# COMPUTE_CLUSTER_ARM_COREPACK_0_COMPUTE_CLUSTER_ARM_COREPACK_0_APBADDR_DBG_CPU0_000730010000h register map
Vendor: Texas Instruments
Peripheral module from a debugger description file (folder am62L).
Registers are 32-bit, read-write, reset 0x0 unless marked. A register's access mark holds for its fields unless they carry their own. Offsets are as the file gives them; lines under a group give offsets from that group; [hi:lo] are bit positions; {n}, {i} and the like mark numbered series; 'fields as' and 'values as' point back to an identical list; <NAME> marks a mode.

## COMPUTE_CLUSTER_ARM_COREPACK_0_APBADDR_DBG_CPU0 (part 1 of 2)
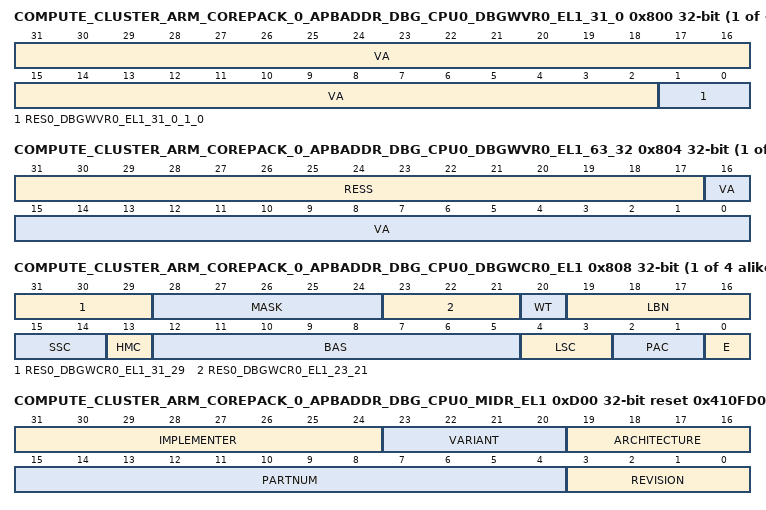
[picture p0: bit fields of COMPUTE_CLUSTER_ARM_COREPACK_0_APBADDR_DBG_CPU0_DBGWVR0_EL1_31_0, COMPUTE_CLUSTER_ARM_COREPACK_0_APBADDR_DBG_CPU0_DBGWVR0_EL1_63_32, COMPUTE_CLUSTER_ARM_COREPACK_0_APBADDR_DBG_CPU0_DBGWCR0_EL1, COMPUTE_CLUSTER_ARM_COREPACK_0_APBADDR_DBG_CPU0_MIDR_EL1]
{0x800+0x10*i} COMPUTE_CLUSTER_ARM_COREPACK_0_APBADDR_DBG_CPU0_DBGWVR{i}_EL1_31_0 (i=0..3) — Debug Watchpoint Value Register {i}
  [31:2] VA — Bits[48:2] of the address value for comparison.ARM deprecates setting DBGWVR<n>_EL1[2] == 1.
  [1:0] RES0_DBGWVR{i}_EL1_31_0_1_0 — Reserved, RES0.
{0x804+0x10*i} COMPUTE_CLUSTER_ARM_COREPACK_0_APBADDR_DBG_CPU0_DBGWVR{i}_EL1_63_32 (i=0..3) — Debug Watchpoint Extended Value Register {i}
  [31:17] RESS — Reserved, Sign extended. Hardwired to the value of the sign bit, bit [48]. Hardware and software must treat this field as RES0 if bit[48] is 0, and as RES1 if bit[48] is 1.
  [16:0] VA — Bits[48:2] of the address value for comparison.ARM deprecates setting DBGWVR<n>_EL1[2] == 1.
{0x808+0x10*i} COMPUTE_CLUSTER_ARM_COREPACK_0_APBADDR_DBG_CPU0_DBGWCR{i}_EL1 (i=0..3) — Debug Watchpoint Control Register {i}
  [31:29] RES0_DBGWCR{i}_EL1_31_29 — Reserved, RES0.
  [28:24] MASK — Address mask. Only objects up to 2GB can be watched using a single mask. 00000 No mask. 00001 Reserved. 00010 Reserved. Other values mask the corresponding number of address bits, from 0b00011 masking 3 address bits [0x00000007 mask for address] to 0b11111 masking 31 address bits [0x7FFFFFFF mask for address].
  [23:21] RES0_DBGWCR{i}_EL1_23_21 — Reserved, RES0.
  [20] WT — Watchpoint type. Possible values are: 0 Unlinked data address match. 1 Linked data address match.
  [19:16] LBN — Linked breakpoint number. For Linked data address watchpoints, this specifies the index of the Context-matching breakpoint linked to.
  [15:14] SSC — Security state control. Determines the security states under which a watchpoint debug event for watchpoint n is generated. This field must be interpreted along with the HMC and PAC fields.
  [13] HMC — Higher mode control. Determines the debug perspective for deciding when a watchpoint debug event for watchpoint n is generated. This field must be interpreted along with the SSC and PAC fields.
  [12:5] BAS — Byte address select. Each bit of this field selects whether a byte from within the word or double-word addressed by DBGWVR<n>_EL1 is being watched.BASDescriptionxxxxxxx1Match byte at DBGWVR<n>_EL1xxxxxx1xMatch byte at DBGWVR<n>_EL1+1xxxxx1xxMatch byte at DBGWVR<n>_EL1+2xxxx1xxxMatch byte at DBGWVR<n>_EL1+3In cases where DBGWVR<n>_EL1 addresses a double-word:BASDescription, if DBGWVR<n>_EL1[2] == 0xxx1xxxxMatch byte at DBGWVR<n>_EL1+4xx1xxxxxMatch byte at DBGWVR<n>_EL1+5x1xxxxxxMatch byte at DBGWVR<n>_EL1+61xxxxxxxMatch byte at DBGWVR<n>_EL1+7If DBGWVR<n>_EL1[2] == 1, only BAS[3:0] is used. ARM deprecates setting DBGWVR<n>_EL1 == 1.The valid values for BAS are 0b0000000, or a binary number all of whose set bits are contiguous. All other values are reserved and must not be used by software.If BAS is zero, no bytes are watched by this watchpoint.Ignored if E is 0.
  [4:3] LSC — Load/store control. This field enables watchpoint matching on the type of access being made. Possible values of this field are: 01 Match instructions that load from a watchpointed address. 10 Match instructions that store to a watchpointed address. 11 Match instructions that load from or store to a watchpointed address. All other values are reserved, but must behave as if the watchpoint is disabled. Software must not rely on this property as the behavior of reserved values might change in a future revision of the architecture.Ignored if E is 0.
  [2:1] PAC — Privilege of access control. Determines the exception level or levels at which a watchpoint debug event for watchpoint n is generated. This field must be interpreted along with the SSC and HMC fields.
  [0] E — Enable watchpoint n. Possible values are: 0 Watchpoint disabled. 1 Watchpoint enabled.
0xD00 COMPUTE_CLUSTER_ARM_COREPACK_0_APBADDR_DBG_CPU0_MIDR_EL1 reset 0x410FD034 — Main ID Register
  [31:24] IMPLEMENTER — The Implementer code. This field must hold an implementer code that has been assigned by ARM.
  [23:20] VARIANT — An IMPLEMENTATION DEFINED variant number. Typically this field is used to distinguish between different product variants or major revisions of a product.
  [19:16] ARCHITECTURE
  [15:4] PARTNUM — An IMPLEMENTATION DEFINED primary part number for the device. On processors implemented by ARM if the top four bits of the primary part number are 0x0 or 0x7 the variant and architecture are encoded differently
  [3:0] REVISION — An IMPLEMENTATION DEFINED revision number for the device
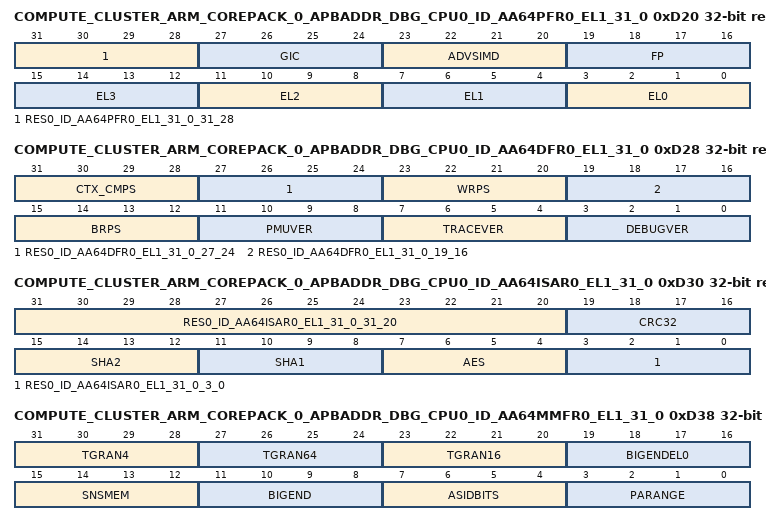
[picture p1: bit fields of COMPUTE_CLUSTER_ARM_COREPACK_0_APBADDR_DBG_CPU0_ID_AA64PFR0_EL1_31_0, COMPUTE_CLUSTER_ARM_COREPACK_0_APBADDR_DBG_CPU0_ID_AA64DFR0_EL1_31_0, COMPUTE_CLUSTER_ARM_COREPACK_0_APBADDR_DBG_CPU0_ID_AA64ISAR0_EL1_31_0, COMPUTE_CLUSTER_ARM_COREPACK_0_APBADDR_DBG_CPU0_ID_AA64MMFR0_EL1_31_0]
0xD20 COMPUTE_CLUSTER_ARM_COREPACK_0_APBADDR_DBG_CPU0_ID_AA64PFR0_EL1_31_0 reset 0x1002222 — Processor Feature Register 0 (low word)
  [31:28] RES0_ID_AA64PFR0_EL1_31_0_31_28 — Reserved, RES0.
  [27:24] GIC — GIC system register interface. Permitted values are: 0000 No GIC system registers are supported. 0001 GICv3 system registers are supported. All other values are reserved.
  [23:20] ADVSIMD — Advanced SIMD. Permitted values are: 0000 Advanced SIMD is implemented. 1111 Advanced SIMD is not implemented. All other values are reserved.
  [19:16] FP — Floating-point. Permitted values are: 0000 Floating-point is implemented. 1111 Floating-point is not implemented. All other values are reserved.
  [4n+3:4n] EL{n} (n=0..3) — EL{n} exception level handling. Permitted values are: 0000 EL{n} is not implemented. 0001 EL{n} can be executed in AArch64 state only. 0010 EL{n} can be executed in either AArch64 or AArch32 state. All other values are reserved.
0xD24 COMPUTE_CLUSTER_ARM_COREPACK_0_APBADDR_DBG_CPU0_ID_AA64PFR0_EL1_63_32 — Processor Feature Register 0 (high word)
  [31:0] RES0_ID_AA64PFR0_EL1_63_32_31_0 — Reserved, RES0.
0xD28 COMPUTE_CLUSTER_ARM_COREPACK_0_APBADDR_DBG_CPU0_ID_AA64DFR0_EL1_31_0 reset 0x10305106 — Debug Feature Register 0 (low word)
  [31:28] CTX_CMPS — Number of breakpoints that are context-aware, minus 1. These are the highest numbered breakpoints.
  [27:24] RES0_ID_AA64DFR0_EL1_31_0_27_24 — Reserved, RES0.
  [23:20] WRPS — Number of watchpoints, minus 1. The value of 0b0000 is reserved.
  [19:16] RES0_ID_AA64DFR0_EL1_31_0_19_16 — Reserved, RES0.
  [15:12] BRPS — Number of breakpoints, minus 1. The value of 0b0000 is reserved.
  [11:8] PMUVER — Performance Monitors extension version. Indicates whether system register interface to Performance Monitors extension is implemented. Permitted values are: 0000 Performance Monitors extension system registers not implemented. 0001 Performance Monitors extension system registers implemented, PMUv3. 1111 IMPLEMENTATION DEFINED form of performance monitors supported, PMUv3 not supported. All other values are reserved.
  [7:4] TRACEVER — Trace extension. Indicates whether system register interface to Trace extension is implemented. Permitted values are: 0000 Trace extension system registers not implemented. 0001 Trace extension system registers implemented. All other values are reserved.A value of 0b0000 only indicates that no system register interface to the trace extension is implemented. A trace extension may nevertheless be implemented without a system register interface.
  [3:0] DEBUGVER — Debug architecture version. Indicates presence of v8-A debug architecture. 0110 v8-A debug architecture. All other values are reserved.
0xD2C COMPUTE_CLUSTER_ARM_COREPACK_0_APBADDR_DBG_CPU0_ID_AA64DFR0_EL1_63_32 — Debug Feature Register 0 (high word)
  [31:0] RES0_ID_AA64DFR0_EL1_63_32_31_0 — Reserved, RES0.
0xD30 COMPUTE_CLUSTER_ARM_COREPACK_0_APBADDR_DBG_CPU0_ID_AA64ISAR0_EL1_31_0 reset 0x11120 — Instruction Set Attribute Register 0 (low word)
  [31:20] RES0_ID_AA64ISAR0_EL1_31_0_31_20 — Reserved, RES0.
  [19:16] CRC32 — CRC32 instructions in AArch64. Possible values of this field are: 0000 No CRC32 instructions implemented. 0001 CRC32B, CRC32H, CRC32W, CRC32X, CRC32CB, CRC32CH, CRC32CW, and CRC32CX instructions implemented. All other values are reserved.This field must have the same value as ID_ISAR5.CRC32. The architecture requires that if CRC32 is supported in one Execution state, it must be supported in both Execution states.
  [15:12] SHA2 — SHA2 instructions in AArch64. Possible values of this field are: 0000 No SHA2 instructions implemented. 0001 SHA256H, SHA256H2, SHA256SU0, and SHA256SU1 instructions implemented. All other values are reserved.
  [11:8] SHA1 — SHA1 instructions in AArch64. Possible values of this field are: 0000 No SHA1 instructions implemented. 0001 SHA1C, SHA1P, SHA1M, SHA1H, SHA1SU0, and SHA1SU1 instructions implemented. All other values are reserved.
  [7:4] AES — AES instructions in AArch64. Possible values of this field are: 0000 No AES instructions implemented. 0001 AESE, AESD, AESMC, and AESIMC instructions implemented. 0010 As for 0b0001, plus PMULL/PMULL2 instructions operating on 64-bit data quantities.
  [3:0] RES0_ID_AA64ISAR0_EL1_31_0_3_0 — Reserved, RES0.
0xD34 COMPUTE_CLUSTER_ARM_COREPACK_0_APBADDR_DBG_CPU0_ID_AA64ISAR0_EL1_63_32 — Instruction Set Attribute Register 0 (high word)
  [31:0] RES0_ID_AA64ISAR0_EL1_63_32_31_0 — Reserved, RES0.
0xD38 COMPUTE_CLUSTER_ARM_COREPACK_0_APBADDR_DBG_CPU0_ID_AA64MMFR0_EL1_31_0 reset 0x1122 — Memory Model Feature Register 0 (low word)
  [31:28] TGRAN4 — Support for 4 Kbyte memory translation granule size. Permitted values are: 0000 4 KB granule supported. 1111 4 KB granule not supported. All other values are reserved.
  [27:24] TGRAN64 — Support for 64 Kbyte memory translation granule size. Permitted values are: 0000 64 KB granule supported. 1111 64 KB granule not supported. All other values are reserved.
  [23:20] TGRAN16 — Support for 16 Kbyte memory translation granule size. Permitted values are: 0000 16 KB granule not supported. 0001 16 KB granule supported. All other values are reserved.
  [19:16] BIGENDEL0 — Mixed-endian support at EL0 only. Permitted values are: 0000 No mixed-endian support at EL0. The SCTLR_EL1.E0E bit has a fixed value. 0001 Mixed-endian support at EL0. The SCTLR_EL1.E0E bit can be configured. All other values are reserved.This field is invalid and is RES0 if the BigEnd field, bits [11:8], is not 0b0000.
  [15:12] SNSMEM — Secure versus Non-secure Memory distinction. Permitted values are: 0000 Does not support a distinction between Secure and Non-secure Memory. 0001 Does support a distinction between Secure and Non-secure Memory. All other values are reserved.
  [11:8] BIGEND — Mixed-endian configuration support. Permitted values are: 0000 No mixed-endian support. The SCTLR_ELx.EE bits have a fixed value. See the BigEndEL0 field, bits[19:16], for whether EL0 supports mixed-endian. 0001 Mixed-endian support. The SCTLR_ELx.EE and SCTLR_EL1.E0E bits can be configured. All other values are reserved.
  [7:4] ASIDBITS — Number of ASID bits. Permitted values are: 0000 8 bits. 0010 16 bits. All other values are reserved.
  [3:0] PARANGE — Physical Address range supported. Permitted values are: 0000 32 bits, 4 GB. 0001 36 bits, 64 GB. 0010 40 bits, 1 TB. 0011 42 bits, 4 TB. 0100 44 bits, 16 TB. 0101 48 bits, 256 TB. All other values are reserved.
0xD3C COMPUTE_CLUSTER_ARM_COREPACK_0_APBADDR_DBG_CPU0_ID_AA64MMFR0_EL1_63_32 — Memory Model Feature Register 0 (high word)
  [31:0] RES0_ID_AA64MMFR0_EL1_63_32_31_0 — Reserved, RES0.
0xD40 COMPUTE_CLUSTER_ARM_COREPACK_0_APBADDR_DBG_CPU0_ID_AA64PFR1_EL1_31_0 — Processor Feature Register 1 (low word)
  [31:0] RES0_ID_AA64PFR1_EL1_31_0_31_0 — Reserved, RES0.
0xD44 COMPUTE_CLUSTER_ARM_COREPACK_0_APBADDR_DBG_CPU0_ID_AA64PFR1_EL1_63_32 — Processor Feature Register 1 (high word)
  [31:0] RES0_ID_AA64PFR1_EL1_63_32_31_0 — Reserved, RES0.
0xD48 COMPUTE_CLUSTER_ARM_COREPACK_0_APBADDR_DBG_CPU0_ID_AA64DFR1_EL1_31_0 — Auxiliary Feature Register 1 (low word)
  [31:0] RES0_ID_AA64DFR1_EL1_31_0_31_0 — Reserved, RES0.
0xD4C COMPUTE_CLUSTER_ARM_COREPACK_0_APBADDR_DBG_CPU0_ID_AA64DFR1_EL1_63_32 — Auxiliary Feature Register 1 (high word)
  [31:0] RES0_ID_AA64DFR1_EL1_63_32_31_0 — Reserved, RES0.
0xD50 COMPUTE_CLUSTER_ARM_COREPACK_0_APBADDR_DBG_CPU0_ID_AA64ISAR1_EL1_31_0 — Instruction Set Attribute Register 1 (low word)
  [31:0] RES0_ID_AA64ISAR1_EL1_31_0_31_0 — Reserved, RES0.
0xD54 COMPUTE_CLUSTER_ARM_COREPACK_0_APBADDR_DBG_CPU0_ID_AA64ISAR1_EL1_63_32 — Instruction Set Attribute Register 1 (high word)
  [31:0] RES0_ID_AA64ISAR1_EL1_63_32_31_0 — Reserved, RES0.
0xD58 COMPUTE_CLUSTER_ARM_COREPACK_0_APBADDR_DBG_CPU0_ID_AA64MMFR1_EL1_31_0 — Memory Model Feature Register 1 (low word)
  [31:0] RES0_ID_AA64MMFR1_EL1_31_0_31_0 — Reserved, RES0.
0xD5C COMPUTE_CLUSTER_ARM_COREPACK_0_APBADDR_DBG_CPU0_ID_AA64MMFR1_EL1_63_32 — Memory Model Feature Register 1 (high word)
  [31:0] RES0_ID_AA64MMFR1_EL1_63_32_31_0 — Reserved, RES0.
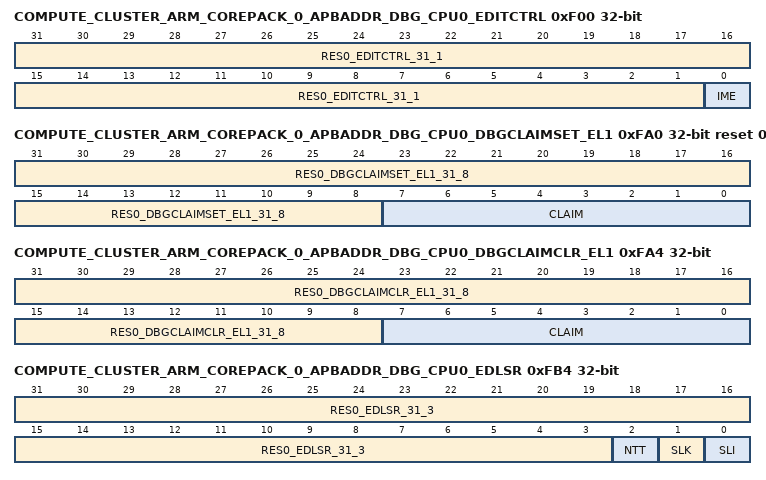
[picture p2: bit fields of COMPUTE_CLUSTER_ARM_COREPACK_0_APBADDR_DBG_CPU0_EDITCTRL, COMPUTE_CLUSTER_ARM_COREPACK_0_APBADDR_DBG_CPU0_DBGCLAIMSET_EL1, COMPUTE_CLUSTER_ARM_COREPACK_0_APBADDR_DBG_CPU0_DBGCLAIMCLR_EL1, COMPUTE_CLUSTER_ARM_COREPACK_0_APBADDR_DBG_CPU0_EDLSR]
0xF00 COMPUTE_CLUSTER_ARM_COREPACK_0_APBADDR_DBG_CPU0_EDITCTRL — External Debug Integration mode Control Register
  [31:1] RES0_EDITCTRL_31_1 — Reserved, RES0.
  [0] IME — Integration mode enable. When IME == 1, the device reverts to an integration mode to enable integration testing or topology detection. The integration mode behavior is IMPLEMENTATION DEFINED. 0 Normal operation. 1 Integration mode enabled.
0xFA0 COMPUTE_CLUSTER_ARM_COREPACK_0_APBADDR_DBG_CPU0_DBGCLAIMSET_EL1 reset 0xFF — Debug Claim Tag Set Register
  [31:8] RES0_DBGCLAIMSET_EL1_31_8 — Reserved, RAZ/SBZ. Software can rely on these bits Reading as zero, and must use a should-be-zero policy on writes. Implementations must ignore writes.
  [7:0] CLAIM — Claim set bits. RAO.Writing a 1 to one of these bits sets the corresponding CLAIM bit to 1. This is an indirect write to the CLAIM bits.A single write operation can set multiple bits to 1. Writing 0 to one of these bits has no effect.
0xFA4 COMPUTE_CLUSTER_ARM_COREPACK_0_APBADDR_DBG_CPU0_DBGCLAIMCLR_EL1 — Debug Claim Tag Clear Register
  [31:8] RES0_DBGCLAIMCLR_EL1_31_8 — Reserved, RAZ/SBZ. Software can rely on these bits Reading as zero, and must use a should-be-zero policy on writes. Implementations must ignore writes.
  [7:0] CLAIM — Claim clear bits. Reading this field returns the current value of the CLAIM bits.Writing a 1 to one of these bits clears the corresponding CLAIM bit to 0. This is an indirect write to the CLAIM bits.A single write operation can clear multiple bits to 0. Writing 0 to one of these bits has no effect.
0xFA8 COMPUTE_CLUSTER_ARM_COREPACK_0_APBADDR_DBG_CPU0_EDDEVAFF0 reset 0x80000000 — External Debug Device Affinity Register 0
  [31:0] EDDEVAFF0 — MPIDR_EL1 low half. Read-only copy of the low half of MPIDR_EL1, as seen from the highest implemented exception level.
0xFAC COMPUTE_CLUSTER_ARM_COREPACK_0_APBADDR_DBG_CPU0_EDDEVAFF1 — External Debug Device Affinity Register 1
  [31:0] EDDEVAFF1 — MPIDR_EL1 high half. Read-only copy of the high half of MPIDR_EL1, as seen from the highest implemented exception level.
0xFB0 COMPUTE_CLUSTER_ARM_COREPACK_0_APBADDR_DBG_CPU0_EDLAR — External Debug Lock Access Register
  [31:0] KEY — Lock Access control. Writing the key value 0xC5ACCE55 to this field unlocks the lock, enabling write accesses to this component's registers through a memory-mapped interface.Writing any other value to this register locks the lock, disabling write accesses to this component's registers through a memory mapped interface.
0xFB4 COMPUTE_CLUSTER_ARM_COREPACK_0_APBADDR_DBG_CPU0_EDLSR — External Debug Lock Status Register
  [31:3] RES0_EDLSR_31_3 — Reserved, RES0.
  [2] NTT — Not thirty-two bit access required. RAZ.
  [1] SLK — Software lock status for this component. For an access to LSR that is not a memory-mapped access, or when the software lock is not implemented, this field is RES0.For memory-mapped accesses when the software lock is implemented, possible values of this field are: 0 Lock clear. Writes are permitted to this component's registers. 1 Lock set. Writes to this component's registers are ignored, and reads have no side effects.
  [0] SLI — Software lock implemented. For an access to LSR that is not a memory-mapped access, this field is RAZ. For memory-mapped accesses, the value of this field is IMPLEMENTATION DEFINED. Permitted values are: 0 Software lock not implemented or not memory-mapped access. 1 Software lock implemented and memory-mapped access.
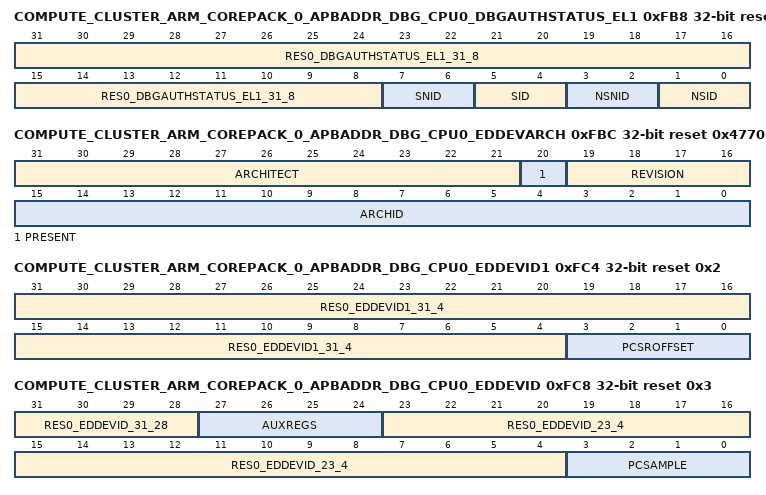
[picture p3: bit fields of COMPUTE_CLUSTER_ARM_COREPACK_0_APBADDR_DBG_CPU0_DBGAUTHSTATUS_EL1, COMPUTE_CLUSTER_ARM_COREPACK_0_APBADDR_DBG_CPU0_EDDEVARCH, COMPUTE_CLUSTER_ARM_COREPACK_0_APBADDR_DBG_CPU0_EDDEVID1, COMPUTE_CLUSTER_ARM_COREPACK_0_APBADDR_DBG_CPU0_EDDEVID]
0xFB8 COMPUTE_CLUSTER_ARM_COREPACK_0_APBADDR_DBG_CPU0_DBGAUTHSTATUS_EL1 reset 0xAA — Debug Authentication Status register
  [31:8] RES0_DBGAUTHSTATUS_EL1_31_8 — Reserved, RES0.
  [7:6] SNID — Secure non-invasive debug. Possible values of this field are: 00 Not implemented. EL3 is not implemented and the processor is Non-secure. 10 Implemented and disabled. ExternalSecureNoninvasiveDebugEnabled[] == FALSE. 11 Implemented and enabled. ExternalSecureNoninvasiveDebugEnabled[] == TRUE. Other values are reserved.
  [5:4] SID — Secure invasive debug. Possible values of this field are: 00 Not implemented. EL3 is not implemented and the processor is Non-secure. 10 Implemented and disabled. ExternalSecureInvasiveDebugEnabled[] == FALSE. 11 Implemented and enabled. ExternalSecureInvasiveDebugEnabled[] == TRUE. Other values are reserved.
  [3:2] NSNID — Non-secure non-invasive debug. Possible values of this field are: 00 Not implemented. EL3 is not implemented and the processor is Secure. 10 Implemented and disabled. ExternalNoninvasiveDebugEnabled[] == FALSE. 11 Implemented and enabled. ExternalNoninvasiveDebugEnabled[] == TRUE. Other values are reserved.
  [1:0] NSID — Non-secure invasive debug. Possible values of this field are: 00 Not implemented. EL3 is not implemented and the processor is Secure. 10 Implemented and disabled. ExternalInvasiveDebugEnabled[] == FALSE. 11 Implemented and enabled. ExternalInvasiveDebugEnabled[] == TRUE. Other values are reserved.
0xFBC COMPUTE_CLUSTER_ARM_COREPACK_0_APBADDR_DBG_CPU0_EDDEVARCH reset 0x47706A15 — External Debug Device Architecture Register
  [31:21] ARCHITECT — Defines the architecture of the component. For debug, this is ARM Limited.Bits [31:28] are the JEP 106 continuation code, 0x4.Bits [27:21] are the JEP 106 ID code, 0x3B.
  [20] PRESENT — When set to 1, indicates that the DEVARCH is present.This field is 1 in v8-A.
  [19:16] REVISION — Defines the architecture revision. For architectures defined by ARM this is the minor revision.For debug, the revision defined by v8-A is 0x0.All other values are reserved.
  [15:0] ARCHID — Defines this part to be a v8-A debug component. For architectures defined by ARM this is further subdivided.For debug:Bits [15:12] are the architecture version, 0x6.Bits [11:0] are the architecture part number, 0xA15.This corresponds to debug architecture version v8-A.
0xFC0 COMPUTE_CLUSTER_ARM_COREPACK_0_APBADDR_DBG_CPU0_EDDEVID2 — External Debug Device ID Register 2
  [31:0] RES0_EDDEVID2_31_0 — Reserved, RES0.
0xFC4 COMPUTE_CLUSTER_ARM_COREPACK_0_APBADDR_DBG_CPU0_EDDEVID1 reset 0x2 — External Debug Device ID Register 1
  [31:4] RES0_EDDEVID1_31_4 — Reserved, RES0.
  [3:0] PCSROFFSET — This field indicates the offset applied to PC samples returned by reads of EDPCSR. Permitted values of this field in v8-A are: 0000 EDPCSR not implemented. 0010 EDPCSR implemented, and samples have no offset applied and do not sample the instruction set state in AArch32 state.
0xFC8 COMPUTE_CLUSTER_ARM_COREPACK_0_APBADDR_DBG_CPU0_EDDEVID reset 0x3 — External Debug Device ID Register 0
  [31:28] RES0_EDDEVID_31_28 — Reserved, RES0.
  [27:24] AUXREGS — Indicates support for Auxiliary registers. Permitted values for this field are: 0000 None supported. 0001 Support for External Debug Auxiliary Control Register, EDACR. All other values are reserved.
  [23:4] RES0_EDDEVID_23_4 — Reserved, RES0.
  [3:0] PCSAMPLE — Indicates the level of Sample-based profiling support using external debug registers 40 through 43. Permitted values of this field in v8-A are: 0000 Architecture-defined form of Sample-based profiling not implemented. 0010 EDPCSR and EDCIDSR are implemented [only permitted if EL3 and EL2 are not implemented]. 0011 EDPCSR, EDCIDSR, and EDVIDSR are implemented. All other values are reserved.
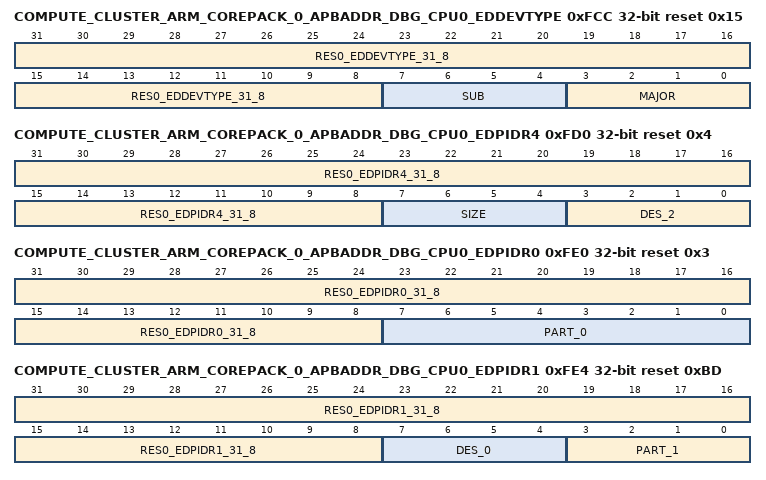
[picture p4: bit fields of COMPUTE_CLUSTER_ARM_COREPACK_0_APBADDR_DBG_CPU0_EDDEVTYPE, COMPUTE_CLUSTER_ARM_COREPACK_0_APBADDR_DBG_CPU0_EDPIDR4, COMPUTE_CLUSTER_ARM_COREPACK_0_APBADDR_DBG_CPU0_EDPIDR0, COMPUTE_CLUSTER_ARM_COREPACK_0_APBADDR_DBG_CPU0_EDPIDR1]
0xFCC COMPUTE_CLUSTER_ARM_COREPACK_0_APBADDR_DBG_CPU0_EDDEVTYPE reset 0x15 — External Debug Device Type Register
  [31:8] RES0_EDDEVTYPE_31_8 — Reserved, RES0.
  [7:4] SUB — Subtype. Must read as 0x1 to indicate this is a processor component.
  [3:0] MAJOR — Major type. Must read as 0x5 to indicate this is a debug logic component.
0xFD0 COMPUTE_CLUSTER_ARM_COREPACK_0_APBADDR_DBG_CPU0_EDPIDR4 reset 0x4 — External Debug Peripheral Identification Register 4
  [31:8] RES0_EDPIDR4_31_8 — Reserved, RES0.
  [7:4] SIZE — Size of the component. RAZ. Log2 of the number of 4KB pages from the start of the component to the end of the component ID registers.
  [3:0] DES_2 — Designer, JEP106 continuation code, least significant nibble. For ARM Limited, this field is 0b0100.
0xFE0 COMPUTE_CLUSTER_ARM_COREPACK_0_APBADDR_DBG_CPU0_EDPIDR0 reset 0x3 — External Debug Peripheral Identification Register 0
  [31:8] RES0_EDPIDR0_31_8 — Reserved, RES0.
  [7:0] PART_0 — Part number, least significant byte.
0xFE4 COMPUTE_CLUSTER_ARM_COREPACK_0_APBADDR_DBG_CPU0_EDPIDR1 reset 0xBD — External Debug Peripheral Identification Register 1
  [31:8] RES0_EDPIDR1_31_8 — Reserved, RES0.
  [7:4] DES_0 — Designer, least significant nibble of JEP106 ID code. For ARM Limited, this field is 0b1011.
  [3:0] PART_1 — Part number, most significant nibble.
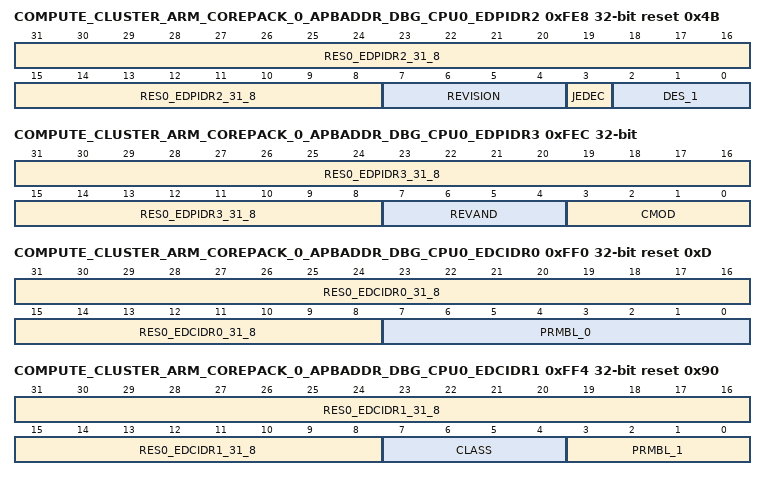
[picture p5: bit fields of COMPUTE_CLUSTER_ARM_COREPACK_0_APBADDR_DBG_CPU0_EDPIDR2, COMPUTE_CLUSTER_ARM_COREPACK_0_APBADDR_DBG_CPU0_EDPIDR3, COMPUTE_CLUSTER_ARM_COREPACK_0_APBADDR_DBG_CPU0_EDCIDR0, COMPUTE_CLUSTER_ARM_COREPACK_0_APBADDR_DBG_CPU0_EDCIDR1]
0xFE8 COMPUTE_CLUSTER_ARM_COREPACK_0_APBADDR_DBG_CPU0_EDPIDR2 reset 0x4B — External Debug Peripheral Identification Register 2
  [31:8] RES0_EDPIDR2_31_8 — Reserved, RES0.
  [7:4] REVISION — Part major revision. Parts can also use this field to extend Part number to 16-bits.
  [3] JEDEC — RAO. Indicates a JEP106 identity code is used.
  [2:0] DES_1 — Designer, most significant bits of JEP106 ID code. For ARM Limited, this field is 0b011.
0xFEC COMPUTE_CLUSTER_ARM_COREPACK_0_APBADDR_DBG_CPU0_EDPIDR3 — External Debug Peripheral Identification Register 3
  [31:8] RES0_EDPIDR3_31_8 — Reserved, RES0.
  [7:4] REVAND — Part minor revision. Parts using EDPIDR2.REVISION as an extension to the Part number must use this field as a major revision number.
  [3:0] CMOD — Customer modified. Indicates someone other than the Designer has modified the component.
0xFF0 COMPUTE_CLUSTER_ARM_COREPACK_0_APBADDR_DBG_CPU0_EDCIDR0 reset 0xD — External Debug Component Identification Register 0
  [31:8] RES0_EDCIDR0_31_8 — Reserved, RES0.
  [7:0] PRMBL_0 — Preamble. Must read as 0x0D.
0xFF4 COMPUTE_CLUSTER_ARM_COREPACK_0_APBADDR_DBG_CPU0_EDCIDR1 reset 0x90 — External Debug Component Identification Register 1
  [31:8] RES0_EDCIDR1_31_8 — Reserved, RES0.
  [7:4] CLASS — Component class. Reads as 0x9, debug component.
  [3:0] PRMBL_1 — Preamble. RAZ.
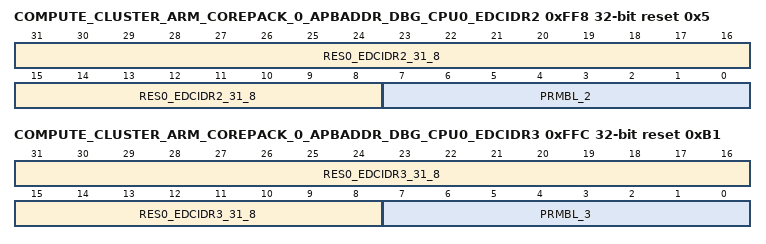
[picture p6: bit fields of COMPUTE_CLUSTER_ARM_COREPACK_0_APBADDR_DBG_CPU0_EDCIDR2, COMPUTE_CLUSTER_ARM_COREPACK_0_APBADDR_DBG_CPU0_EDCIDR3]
0xFF8 COMPUTE_CLUSTER_ARM_COREPACK_0_APBADDR_DBG_CPU0_EDCIDR2 reset 0x5 — External Debug Component Identification Register 2
  [31:8] RES0_EDCIDR2_31_8 — Reserved, RES0.
  [7:0] PRMBL_2 — Preamble. Must read as 0x05.
0xFFC COMPUTE_CLUSTER_ARM_COREPACK_0_APBADDR_DBG_CPU0_EDCIDR3 reset 0xB1 — External Debug Component Identification Register 3
  [31:8] RES0_EDCIDR3_31_8 — Reserved, RES0.
  [7:0] PRMBL_3 — Preamble. Must read as 0xB1.
